# f28p65x_dcsm_z1_regs register map
Vendor: Texas Instruments
Peripheral module from a debugger description file (folder C2000).
Address unit: 16 bits
Registers are 32-bit, read-only, no defined reset value unless marked. A register's access mark holds for its fields unless they carry their own. Offsets are as the file gives them; lines under a group give offsets from that group; [hi:lo] are bit positions; {n}, {i} and the like mark numbered series; 'fields as' and 'values as' point back to an identical list; <NAME> marks a mode.

## DCSM_Z1_REGS — DCSM Z1 Registers
0x00 Z1_LINKPOINTER — Zone 1 Link Pointer
  [13:0] LINKPOINTER — Zone1 LINK Pointer
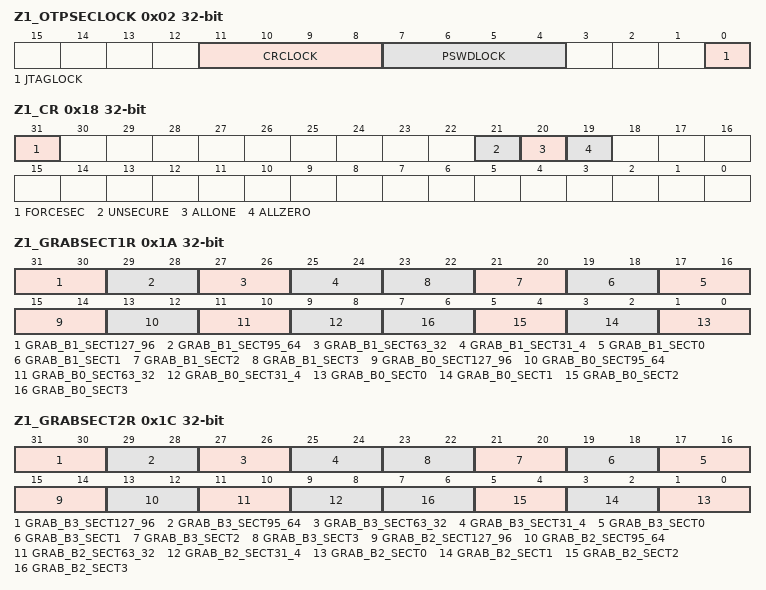
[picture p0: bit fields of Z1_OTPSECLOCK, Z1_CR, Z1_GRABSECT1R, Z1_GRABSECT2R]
0x02 Z1_OTPSECLOCK — Zone 1 OTP Secure Lock
  [11:8] CRCLOCK — Zone1 CRC Lock.
  [7:4] PSWDLOCK — Zone1 Password Lock.
  [0] JTAGLOCK — JTAG Lock Status
0x04 Z1_JLM_ENABLE — Zone 1 JTAGLOCK Enable Register
  [3:0] Z1_JLM_ENABLE — Zone1 JLM_ENABLE register.
0x06 Z1_LINKPOINTERERR — Link Pointer Error
  [13:0] Z1_LINKPOINTERERR — Error to Resolve Z1 Link pointer from OTP loaded values
{0x6+2i} Z1_GPREG{i} (i=1..4) — Zone 1 General Purpose Register-{i}
  [31:0] GPREG{i} — General Purpose Register-{i}
0x10 Z1_CSMKEY0 rw — Zone 1 CSM Key 0
  [31:0] Z1_CSMKEY0 — Word0 to unlock Zone1, should match Z1_CSMPSWD0.
{0x10+2i} Z1_CSMKEY{i} rw (i=1..3) — Zone 1 CSM Key {i}
  [31:0] Z1_CSMKEY{i} — Word{i} to unlock Zone1, should match Z1_CSMPSWD{i}
0x18 Z1_CR access per field — Zone 1 CSM Control Register
  [31] FORCESEC rw — Force Secure
  [21] UNSECURE ro — CSMPSWD Match CSMKEY
  [20] ALLONE ro — CSMPSWD All Ones
  [19] ALLZERO ro — CSMPSWD All Zeros
0x1A Z1_GRABSECT1R — Zone 1 Grab Flash Status Register 1
  [31:30] GRAB_B1_SECT127_96 — Grab Flash Bank1 Sector 127-96
  [29:28] GRAB_B1_SECT95_64 — Grab Flash Bank1 Sector 95-64
  [27:26] GRAB_B1_SECT63_32 — Grab Flash Bank1 Sector 63-32
  [25:24] GRAB_B1_SECT31_4 — Grab Flash Bank1 Sector 31-4
  [2n+17:2n+16] GRAB_B1_SECT{n} (n=0..3) — Grab Flash Bank1 Sector {n}
  [15:14] GRAB_B0_SECT127_96 — Grab Flash Bank1 Sector 127-96
  [13:12] GRAB_B0_SECT95_64 — Grab Flash Bank0 Sector 95-64
  [11:10] GRAB_B0_SECT63_32 — Grab Flash Bank0 Sector 63-32
  [9:8] GRAB_B0_SECT31_4 — Grab Flash Bank0 Sector 31-4
  [2n+1:2n] GRAB_B0_SECT{n} (n=0..3) — Grab Flash Bank0 Sector {n}
0x1C Z1_GRABSECT2R — Zone 1 Grab Flash Status Register 2
  [31:30] GRAB_B3_SECT127_96 — Grab Flash Bank3 Sector 127-96
  [29:28] GRAB_B3_SECT95_64 — Grab Flash Bank3 Sector 95-64
  [27:26] GRAB_B3_SECT63_32 — Grab Flash Bank3 Sector 63-32
  [25:24] GRAB_B3_SECT31_4 — Grab Flash Bank3 Sector 31-4
  [2n+17:2n+16] GRAB_B3_SECT{n} (n=0..3) — Grab Flash Bank3 Sector {n}
  [15:14] GRAB_B2_SECT127_96 — Grab Flash Bank2 Sector 127-96
  [13:12] GRAB_B2_SECT95_64 — Grab Flash Bank2 Sector 95-64
  [11:10] GRAB_B2_SECT63_32 — Grab Flash Bank2 Sector 63-32
  [9:8] GRAB_B2_SECT31_4 — Grab Flash Bank2 Sector 31-4
  [2n+1:2n] GRAB_B2_SECT{n} (n=0..3) — Grab Flash Bank2 Sector {n}
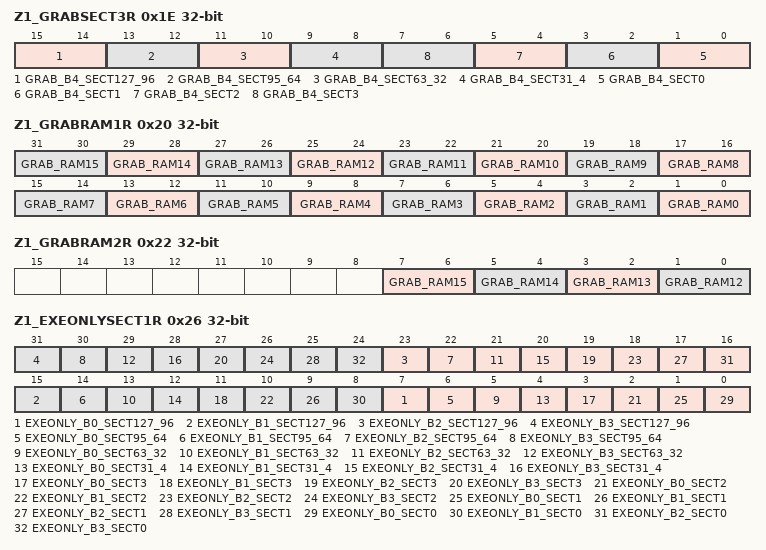
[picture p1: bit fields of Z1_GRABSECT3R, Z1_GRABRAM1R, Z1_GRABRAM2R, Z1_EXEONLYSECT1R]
0x1E Z1_GRABSECT3R — Zone 1 Grab Flash Status Register 3
  [15:14] GRAB_B4_SECT127_96 — Grab Flash Bank4 Sector 127-96
  [13:12] GRAB_B4_SECT95_64 — Grab Flash Bank4 Sector 95-64
  [11:10] GRAB_B4_SECT63_32 — Grab Flash Bank4 Sector 63-32
  [9:8] GRAB_B4_SECT31_4 — Grab Flash Bank4 Sector 31-4
  [2n+1:2n] GRAB_B4_SECT{n} (n=0..3) — Grab Flash Bank4 Sector {n}
0x20 Z1_GRABRAM1R — Zone 1 Grab RAM Status Register 1
  [2n+1:2n] GRAB_RAM{n} (n=10..15) — Grab RAM D{n-10}
  [2n+1:2n] GRAB_RAM{n} (n=0..9) — Grab RAM CPU1.LS{n}
0x22 Z1_GRABRAM2R — Zone 1 Grab RAM Status Register 2
  [7:6] GRAB_RAM15 — Grab RAM CPU2TOCPU1 MSGRAM0_H
  [5:4] GRAB_RAM14 — Grab RAM CPU2TOCPU1 MSGRAM0_L
  [3:2] GRAB_RAM13 — Grab RAM CPU1TOCPU2 MSGRAM0_H
  [1:0] GRAB_RAM12 — Grab RAM CPU1TOCPU2 MSGRAM0_L
0x26 Z1_EXEONLYSECT1R — Zone 1 Execute Only Flash Status Register 1
  [8n+7] EXEONLY_B{n}_SECT127_96 (n=0..3) — Execute-Only Flash Bank{n} Sector 127-96
  [8n+6] EXEONLY_B{n}_SECT95_64 (n=0..3) — Execute-Only Flash Bank{n} Sector 95-64
  [8n+5] EXEONLY_B{n}_SECT63_32 (n=0..3) — Execute-Only Flash Bank{n} Sector 63-32
  [8n+4] EXEONLY_B{n}_SECT31_4 (n=0..3) — Execute-Only Flash Bank{n} Sector 31-4
  [8n+3] EXEONLY_B{n}_SECT3 (n=0..3) — Execute-Only Flash Bank{n} Sector 3
  [8n+2] EXEONLY_B{n}_SECT2 (n=0..3) — Execute-Only Flash Bank{n} Sector 2
  [8n+1] EXEONLY_B{n}_SECT1 (n=0..3) — Execute-Only Flash Bank{n} Sector 1
  [8n] EXEONLY_B{n}_SECT0 (n=0..3) — Execute-Only Flash Bank{n} Sector 0
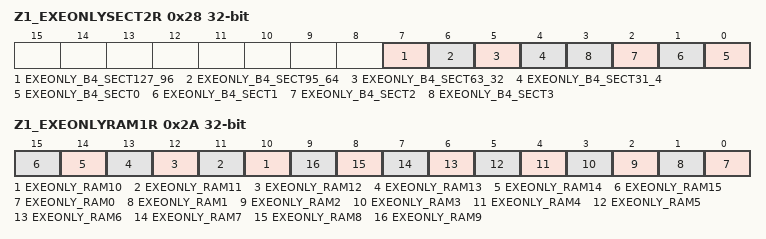
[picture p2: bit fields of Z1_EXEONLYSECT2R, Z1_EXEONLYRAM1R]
0x28 Z1_EXEONLYSECT2R — Zone 1 Execute Only Flash Status Register 2
  [7] EXEONLY_B4_SECT127_96 — Execute-Only Flash Bank4 Sector 127-96
  [6] EXEONLY_B4_SECT95_64 — Execute-Only Flash Bank4 Sector 95-64
  [5] EXEONLY_B4_SECT63_32 — Execute-Only Flash Bank4 Sector 63-32
  [4] EXEONLY_B4_SECT31_4 — Execute-Only Flash Bank4 Sector 31-4
  [n] EXEONLY_B4_SECT{n} (n=0..3) — Execute-Only Flash Bank4 Sector {n}
0x2A Z1_EXEONLYRAM1R — Zone 1 Execute Only RAM Status Register 1
  [n] EXEONLY_RAM{n} (n=10..15) — Execute-Only RAM D{n-10}
  [n] EXEONLY_RAM{n} (n=0..9) — Execute-Only RAM CPU1.LS{n}
{0x2E+2i} Z1_JTAGKEY{i} (i=0..3) — JTAG Unlock Key Register {i}
  [31:0] KEY{i} — JTAGKEY Bits {32i+31}:{32i}
{0x36+2i} Z1_CMACKEY{i} (i=0..3) — Secure Boot CMAC Key Status Register {i}
  [31:0] KEY{i} — CMACKEY Bits {32i+31}:{32i}
0x3E Z1_DIAG — Diagnostics Configuration Register
  [5:4] MPOST_EN — MPOST Enable
